AUTOSAR XML (schema 4-0-3)
package /Nexteer/NvMProxy_swc/ComponentTypes
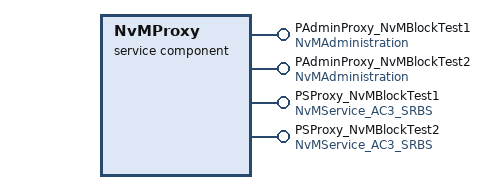
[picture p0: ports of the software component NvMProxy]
  service sw component type NvMProxy
    4 x provide port:
      PAdminProxy_NvMBlockTest1: server-com-spec{operation=SetBlockProtection, queue-length=1}, provided-interface=NvMAdministration
      PAdminProxy_NvMBlockTest2: server-com-spec{operation=SetBlockProtection, queue-length=1}, provided-interface=NvMAdministration
      PSProxy_NvMBlockTest1: provided-interface=NvMService_AC3_SRBS
        provided-com-specs:
          operation=EraseBlock, queue-length=1
          operation=GetErrorStatus, queue-length=1
          operation=InvalidateNvBlock, queue-length=1
          operation=ReadBlock, queue-length=1
          operation=SetRamBlockStatus, queue-length=1
          operation=WriteBlock, queue-length=1
      PSProxy_NvMBlockTest2: provided-interface=NvMService_AC3_SRBS
        provided-com-specs:
          operation=EraseBlock, queue-length=1
          operation=GetErrorStatus, queue-length=1
          operation=InvalidateNvBlock, queue-length=1
          operation=ReadBlock, queue-length=1
          operation=SetRamBlockStatus, queue-length=1
          operation=WriteBlock, queue-length=1
    behavior NvMProxyInternalBehavior
      port-api-options:
        {enable-take-address=true, indirect-api=false, port-defined-argument-value{value=PAdminProxy_NvMBlockTest1_0:2, value-type=NvM_BlockIdType}, port=PAdminProxy_NvMBlockTest1}
        {enable-take-address=true, indirect-api=false, port-defined-argument-value{value=PAdminProxy_NvMBlockTest2_0:3, value-type=NvM_BlockIdType}, port=PAdminProxy_NvMBlockTest2}
        {enable-take-address=false, indirect-api=false, port-defined-argument-value{value=PSProxy_NvMBlockTest1_0:2, value-type=NvM_BlockIdType}, port=PSProxy_NvMBlockTest1}
        {enable-take-address=false, indirect-api=false, port-defined-argument-value{value=PSProxy_NvMBlockTest2_0:3, value-type=NvM_BlockIdType}, port=PSProxy_NvMBlockTest2}
      11 x runnable:
        EraseBlock: can-be-invoked-concurrently=true, symbol=NvMProxy_EraseNvBlock
        GetDataIndex: can-be-invoked-concurrently=true, symbol=NvMProxy_GetDataIndex
        GetErrorStatus: can-be-invoked-concurrently=true, symbol=NvMProxy_GetErrorStatus
        InvalidateNvBlock: can-be-invoked-concurrently=true, symbol=NvMProxy_InvalidateNvBlock
        NvMProxy_MainFunction
        ReadBlock: can-be-invoked-concurrently=true, symbol=NvMProxy_ReadBlock
        RestoreBlockDefaults: can-be-invoked-concurrently=true, symbol=NvMProxy_RestoreBlockDefaults
        SetBlockProtection: can-be-invoked-concurrently=true, symbol=NvMProxy_SetBlockProtection
        SetDataIndex: symbol=NvM_SetDataIndex
        SetRamBlockStatus: can-be-invoked-concurrently=true, symbol=NvMProxy_SetRamBlockStatus
        WriteBlock: can-be-invoked-concurrently=true, symbol=NvMProxy_WriteBlock
  swc implementation NvMProxyImplementation: behavior=NvMProxyInternalBehavior
    code-descriptors:
      code Default: artifact-descriptors=autosar-engineering-object={short-label=Default, category=SWSRC}
